AUTOSAR XML (schema 4-2-1)
package /RootP_ASWC_M419
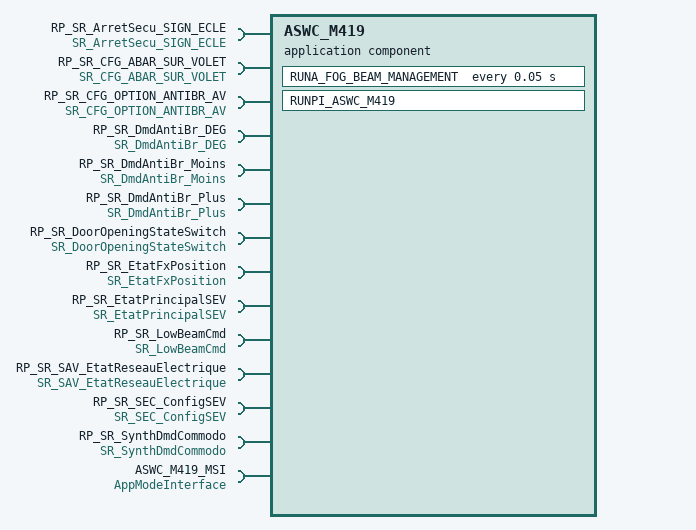
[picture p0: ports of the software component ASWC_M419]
  application sw component type ASWC_M419
    4 x provide/require port:
      PRP_SR_FrontFogBeamCmd: nonqueued-receiver-com-spec{data-element=FrontFogBeamCmd, enable-update=0, handle-data-status=1, handle-never-received=0, init-value=CONST_tLOG_0:0}, provided-required-interface=SR_FrontFogBeamCmd
      PRP_SR_LowBeamFOGCmd: nonqueued-receiver-com-spec{data-element=LowBeamFOGCmd, enable-update=0, handle-data-status=1, handle-never-received=0, init-value=CONST_tLOG_0:0}, provided-required-interface=SR_LowBeamFOGCmd
      PRP_SR_PositionByFogBeam: nonqueued-receiver-com-spec{data-element=PositionByFogBeam, enable-update=0, handle-data-status=1, handle-never-received=0, init-value=CONST_tLOG_0:0}, provided-required-interface=SR_PositionByFogBeam
      PRP_SR_RearFogBeamCmd: nonqueued-receiver-com-spec{data-element=RearFogBeamCmd, enable-update=0, handle-data-status=1, handle-never-received=0, init-value=CONST_tLOG_0:0}, provided-required-interface=SR_RearFogBeamCmd
    14 x require port:
      RP_SR_ArretSecu_SIGN_ECLE: nonqueued-receiver-com-spec{data-element=ArretSecu_SIGN_ECLE, enable-update=0, handle-data-status=1, handle-never-received=0, init-value=CONST_tLOG_1:1}, required-interface=SR_ArretSecu_SIGN_ECLE
      RP_SR_CFG_ABAR_SUR_VOLET: nonqueued-receiver-com-spec{data-element=CFG_ABAR_SUR_VOLET, enable-update=0, handle-data-status=1, handle-never-received=0, init-value=CONST_tLOG_0:0}, required-interface=SR_CFG_ABAR_SUR_VOLET
      RP_SR_CFG_OPTION_ANTIBR_AV: nonqueued-receiver-com-spec{data-element=CFG_OPTION_ANTIBR_AV, enable-update=0, handle-data-status=1, handle-never-received=0, init-value=CONST_tLOG_0:0}, required-interface=SR_CFG_OPTION_ANTIBR_AV
      RP_SR_DmdAntiBr_DEG: nonqueued-receiver-com-spec{data-element=DmdAntiBr_DEG, enable-update=0, handle-data-status=1, handle-never-received=0, init-value=CONST_tLOG_0:0}, required-interface=SR_DmdAntiBr_DEG
      RP_SR_DmdAntiBr_Moins: nonqueued-receiver-com-spec{data-element=DmdAntiBr_Moins, enable-update=0, handle-data-status=1, handle-never-received=0, init-value=CONST_tLOG_0:0}, required-interface=SR_DmdAntiBr_Moins
      RP_SR_DmdAntiBr_Plus: nonqueued-receiver-com-spec{data-element=DmdAntiBr_Plus, enable-update=0, handle-data-status=1, handle-never-received=0, init-value=CONST_tLOG_0:0}, required-interface=SR_DmdAntiBr_Plus
      RP_SR_DoorOpeningStateSwitch: nonqueued-receiver-com-spec{data-element=DoorOpeningState, enable-update=0, handle-data-status=1, handle-never-received=0, init-value=CONST_DoorOpeningState_tOpeningPosition_eMVA_None:0}, required-interface=SR_DoorOpeningStateSwitch
      RP_SR_EtatFxPosition: nonqueued-receiver-com-spec{data-element=EtatFxPosition, enable-update=0, handle-data-status=1, handle-never-received=0, init-value=CONST_tLOG_0:0}, required-interface=SR_EtatFxPosition
      RP_SR_EtatPrincipalSEV: nonqueued-receiver-com-spec{data-element=EtatPrincipalSEV, enable-update=0, handle-data-status=1, handle-never-received=0, init-value=CONST_EtatPrincipalSEV_t_SEV_SEV_Arret:105}, required-interface=SR_EtatPrincipalSEV
      RP_SR_LowBeamCmd: nonqueued-receiver-com-spec{data-element=LowBeamCmd, enable-update=0, handle-data-status=1, handle-never-received=0, init-value=CONST_tLOG_0:0}, required-interface=SR_LowBeamCmd
      RP_SR_SAV_EtatReseauElectrique: nonqueued-receiver-com-spec{data-element=SAV_EtatReseauElectrique, enable-update=0, handle-data-status=1, handle-never-received=0, init-value=CONST_t_cGEE_1_0:0}, required-interface=SR_SAV_EtatReseauElectrique
      RP_SR_SEC_ConfigSEV: nonqueued-receiver-com-spec{data-element=SEC_ConfigSEV, enable-update=0, handle-data-status=1, handle-never-received=0, init-value=CONST_t_cCSEV_4:4}, required-interface=SR_SEC_ConfigSEV
      RP_SR_SynthDmdCommodo: nonqueued-receiver-com-spec{data-element=SynthDmdCommodo, enable-update=0, handle-data-status=1, handle-never-received=0, init-value=CONST_tBYTE_0:0}, required-interface=SR_SynthDmdCommodo
      ASWC_M419_MSI: required-interface=AppModeInterface
    behavior IB_ASWC_M419: data-type-mapping=ApplicationModeMapping, handle-termination-and-restart=NO-SUPPORT
      timing event RUNA_FOG_BEAM_MANAGEMENT_Cyclic: start-on-event=RUNA_FOG_BEAM_MANAGEMENT, period=0.05
        disabled-mode:
          ASWC_M419_MSI.AppMode.APP_WAKEUP
          ASWC_M419_MSI.AppMode.APP_OFF
          ASWC_M419_MSI.AppMode.APP_SYNC_INIT
          ASWC_M419_MSI.AppMode.APP_CONFIG
      swc mode switch event RUNPI_ASWC_M419_ENTRY: start-on-event=RUNPI_ASWC_M419, activation=ON-ENTRY, mode=ASWC_M419_MSI.AppMode.APP_WAKEUP
      runnable RUNA_FOG_BEAM_MANAGEMENT
        data-read-access:
          17 x access:
            dra_RP_SR_ArretSecu_SIGN_ECLE_ArretSecu_SIGN_ECLE: accessed-variable=RP_SR_ArretSecu_SIGN_ECLE.ArretSecu_SIGN_ECLE
            dra_RP_SR_DmdAntiBr_DEG_DmdAntiBr_DEG: accessed-variable=RP_SR_DmdAntiBr_DEG.DmdAntiBr_DEG
            dra_RP_SR_DmdAntiBr_Moins_DmdAntiBr_Moins: accessed-variable=RP_SR_DmdAntiBr_Moins.DmdAntiBr_Moins
            dra_RP_SR_DmdAntiBr_Plus_DmdAntiBr_Plus: accessed-variable=RP_SR_DmdAntiBr_Plus.DmdAntiBr_Plus
            dra_RP_SR_DoorOpeningStateSwitch_DoorOpeningState: accessed-variable=RP_SR_DoorOpeningStateSwitch.DoorOpeningState
            dra_RP_SR_EtatFxPosition_EtatFxPosition: accessed-variable=RP_SR_EtatFxPosition.EtatFxPosition
            dra_RP_SR_EtatPrincipalSEV_EtatPrincipalSEV: accessed-variable=RP_SR_EtatPrincipalSEV.EtatPrincipalSEV
            dra_RP_SR_LowBeamCmd_LowBeamCmd: accessed-variable=RP_SR_LowBeamCmd.LowBeamCmd
            dra_RP_SR_SAV_EtatReseauElectrique_SAV_EtatReseauElectrique: accessed-variable=RP_SR_SAV_EtatReseauElectrique.SAV_EtatReseauElectrique
            dra_RP_SR_SEC_ConfigSEV_SEC_ConfigSEV: accessed-variable=RP_SR_SEC_ConfigSEV.SEC_ConfigSEV
            dra_RP_SR_SynthDmdCommodo_SynthDmdCommodo: accessed-variable=RP_SR_SynthDmdCommodo.SynthDmdCommodo
            dra_RP_SR_CFG_ABAR_SUR_VOLET_CFG_ABAR_SUR_VOLET: accessed-variable=RP_SR_CFG_ABAR_SUR_VOLET.CFG_ABAR_SUR_VOLET
            dra_RP_SR_CFG_OPTION_ANTIBR_AV_CFG_OPTION_ANTIBR_AV: accessed-variable=RP_SR_CFG_OPTION_ANTIBR_AV.CFG_OPTION_ANTIBR_AV
            dra_PRP_SR_FrontFogBeamCmd_FrontFogBeamCmd: accessed-variable=PRP_SR_FrontFogBeamCmd.FrontFogBeamCmd
            dra_PRP_SR_LowBeamFOGCmd_LowBeamFOGCmd: accessed-variable=PRP_SR_LowBeamFOGCmd.LowBeamFOGCmd
            dra_PRP_SR_PositionByFogBeam_PositionByFogBeam: accessed-variable=PRP_SR_PositionByFogBeam.PositionByFogBeam
            dra_PRP_SR_RearFogBeamCmd_RearFogBeamCmd: accessed-variable=PRP_SR_RearFogBeamCmd.RearFogBeamCmd
        data-write-access:
          4 x access:
            dwa_PRP_SR_FrontFogBeamCmd_FrontFogBeamCmd: accessed-variable=PRP_SR_FrontFogBeamCmd.FrontFogBeamCmd
            dwa_PRP_SR_LowBeamFOGCmd_LowBeamFOGCmd: accessed-variable=PRP_SR_LowBeamFOGCmd.LowBeamFOGCmd
            dwa_PRP_SR_PositionByFogBeam_PositionByFogBeam: accessed-variable=PRP_SR_PositionByFogBeam.PositionByFogBeam
            dwa_PRP_SR_RearFogBeamCmd_RearFogBeamCmd: accessed-variable=PRP_SR_RearFogBeamCmd.RearFogBeamCmd
      runnable RUNPI_ASWC_M419
package /RootP_Implementatation
  swc implementation Implementatation_ASWC_M419: programming-language=C, sw-version=1.0.0, vendor-id=1, behavior=IB_ASWC_M419
    code-descriptors:
      code SRC: artifact-descriptors=autosar-engineering-object={short-label=EngObject, category=SWSRC}
    resource consumption Resources
